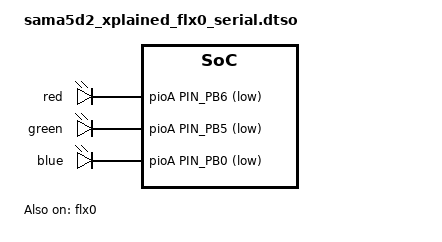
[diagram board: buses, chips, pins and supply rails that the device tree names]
// SPDX-License-Identifier: (GPL-2.0+ OR MIT)
/*
 * sama5d2_xplained_flx0_i2c.dtso - Device Tree file for SAMA5D2 Xplained board
 * overlay blob to configure Flexcom0 as UART for Modbus.
 *
 * Copyright (C) 2020 Microchip Technology Inc. and its subsidiaries
 * Author: Codrin Ciubotariu <codrin.ciubotariu@microchip.com>
 *
 */
/dts-v1/;
/plugin/;

#include <dt-bindings/mfd/atmel-flexcom.h>
#include "sama5d2-pinfunc.h"
#include <dt-bindings/gpio/gpio.h>

&isc {
	status = "disabled";
};

&flx0 {
	status = "okay"; /* conflict with ISC_D2 & ISC_D3 data pins */
};

&{/} {
	leds {
		compatible = "gpio-leds";
		pinctrl-names = "default";
		pinctrl-0 = <&pinctrl_led_gpio_default>;
		status = "okay"; /* conflict with pwm0 */

		red {
			label = "red";
			gpios = <&pioA PIN_PB6 GPIO_ACTIVE_LOW>;
		};


		green {
			label = "green";
			gpios = <&pioA PIN_PB5 GPIO_ACTIVE_LOW>;
			linux,default-trigger = "heartbeat";
		};

		blue {
			label = "blue";
			gpios = <&pioA PIN_PB0 GPIO_ACTIVE_LOW>;
			//linux,default-trigger = "heartbeat";
		};
	};
};

